# STM32F042x register map
File version: 1.0
CPU: 
Registers are 32-bit, read-write, reset 0x0 unless marked. A register's access mark holds for its fields unless they carry their own. Offsets are from the block's base; [hi:lo] are bit positions.

## SPI1 — Serial peripheral interface
Base 0x40013000
Same registers: SPI2 0x40003800
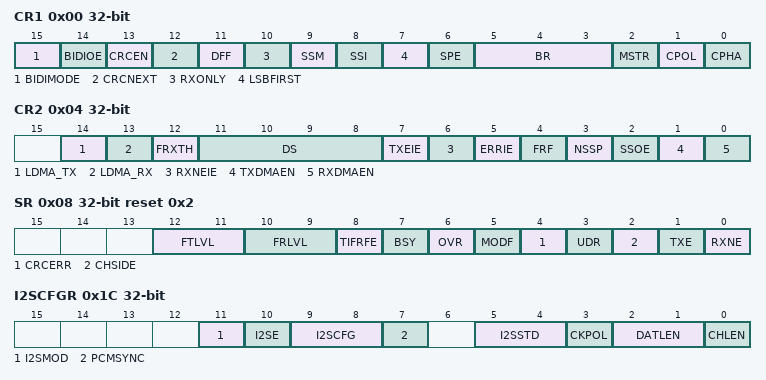
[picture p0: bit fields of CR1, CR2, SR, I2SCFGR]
0x00 CR1 — control register 1
  [15] BIDIMODE — Bidirectional data mode enable
  [14] BIDIOE — Output enable in bidirectional mode
  [13] CRCEN — Hardware CRC calculation enable
  [12] CRCNEXT — CRC transfer next
  [11] DFF — Data frame format
  [10] RXONLY — Receive only
  [9] SSM — Software slave management
  [8] SSI — Internal slave select
  [7] LSBFIRST — Frame format
  [6] SPE — SPI enable
  [5:3] BR — Baud rate control
  [2] MSTR — Master selection
  [1] CPOL — Clock polarity
  [0] CPHA — Clock phase
0x04 CR2 — control register 2
  [14] LDMA_TX — Last DMA transfer for transmission
  [13] LDMA_RX — Last DMA transfer for reception
  [12] FRXTH — FIFO reception threshold
  [11:8] DS — Data size
  [7] TXEIE — Tx buffer empty interrupt enable
  [6] RXNEIE — RX buffer not empty interrupt enable
  [5] ERRIE — Error interrupt enable
  [4] FRF — Frame format
  [3] NSSP — NSS pulse management
  [2] SSOE — SS output enable
  [1] TXDMAEN — Tx buffer DMA enable
  [0] RXDMAEN — Rx buffer DMA enable
0x08 SR access per field reset 0x2 — status register
  [12:11] FTLVL ro — FIFO transmission level
  [10:9] FRLVL ro — FIFO reception level
  [8] TIFRFE ro — TI frame format error
  [7] BSY ro — Busy flag
  [6] OVR ro — Overrun flag
  [5] MODF ro — Mode fault
  [4] CRCERR rw — CRC error flag
  [3] UDR ro — Underrun flag
  [2] CHSIDE ro — Channel side
  [1] TXE ro — Transmit buffer empty
  [0] RXNE ro — Receive buffer not empty
0x0C DR — data register
  [15:0] DR — Data register
0x10 CRCPR reset 0x7 — CRC polynomial register
  [15:0] CRCPOLY
0x14 RXCRCR ro — RX CRC register
  [15:0] RxCRC
0x18 TXCRCR ro — TX CRC register
  [15:0] TxCRC
0x1C I2SCFGR — I2S configuration register
  [11] I2SMOD — I2S mode selection
  [10] I2SE — I2S Enable
  [9:8] I2SCFG — I2S configuration mode
  [7] PCMSYNC — PCM frame synchronization
  [5:4] I2SSTD — I2S standard selection
  [3] CKPOL — Steady state clock polarity
  [2:1] DATLEN — Data length to be transferred
  [0] CHLEN — Channel length (number of bits per audio channel)
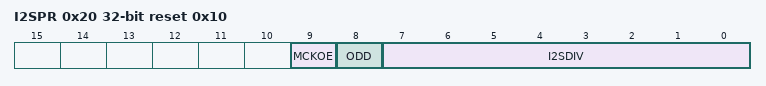
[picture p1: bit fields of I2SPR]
0x20 I2SPR reset 0x10 — I2S prescaler register
  [9] MCKOE — Master clock output enable
  [8] ODD — Odd factor for the prescaler
  [7:0] I2SDIV — I2S Linear prescaler

## PWR — Power control
Base 0x40007000
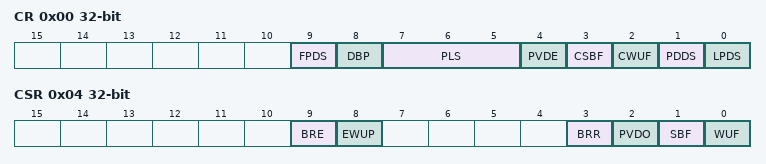
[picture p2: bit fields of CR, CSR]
0x00 CR — power control register
  [9] FPDS — Flash power down in Stop mode
  [8] DBP — Disable backup domain write protection
  [7:5] PLS — PVD level selection
  [4] PVDE — Power voltage detector enable
  [3] CSBF — Clear standby flag
  [2] CWUF — Clear wakeup flag
  [1] PDDS — Power down deepsleep
  [0] LPDS — Low-power deep sleep
0x04 CSR access per field — power control/status register
  [9] BRE rw — Backup regulator enable
  [8] EWUP rw — Enable WKUP pin
  [3] BRR ro — Backup regulator ready
  [2] PVDO ro — PVD output
  [1] SBF ro — Standby flag
  [0] WUF ro — Wakeup flag

## IWDG — Independent watchdog
Base 0x40003000
0x00 KR wo — Key register
  [15:0] KEY — Key value
0x04 PR — Prescaler register
  [2:0] PR — Prescaler divider
0x08 RLR reset 0xFFF — Reload register
  [11:0] RL — Watchdog counter reload value
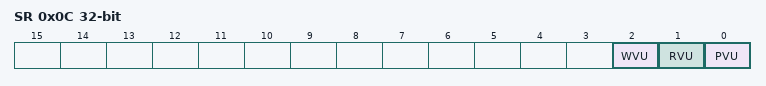
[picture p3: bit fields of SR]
0x0C SR ro — Status register
  [2] WVU — Watchdog counter window value update
  [1] RVU — Watchdog counter reload value update
  [0] PVU — Watchdog prescaler value update
0x10 WINR reset 0xFFF — Window register
  [11:0] WIN — Watchdog counter window value

## WWDG — Window watchdog
Base 0x40002C00
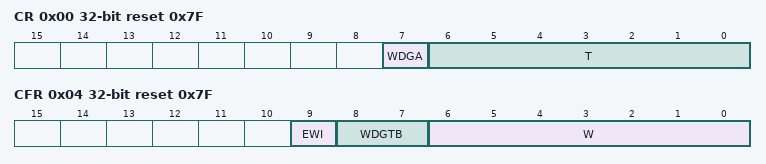
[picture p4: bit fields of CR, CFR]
0x00 CR reset 0x7F — Control register
  [7] WDGA — Activation bit
  [6:0] T — 7-bit counter
0x04 CFR reset 0x7F — Configuration register
  [9] EWI — Early wakeup interrupt
  [8:7] WDGTB — Timer base
  [6:0] W — 7-bit window value
0x08 SR — Status register
  [0] EWIF — Early wakeup interrupt flag
